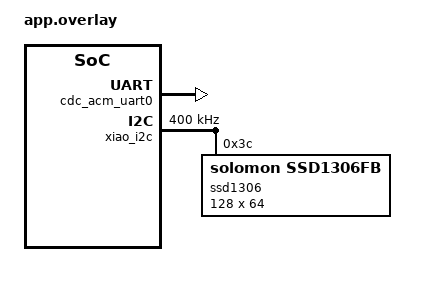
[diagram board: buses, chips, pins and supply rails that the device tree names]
&zephyr_udc0 {
	cdc_acm_uart0: cdc_acm_uart0 {
		compatible = "zephyr,cdc-acm-uart";
	};
};

&xiao_i2c {
	status="okay";
	clock-frequency=<I2C_BITRATE_FAST>;

	ssd1306: ssd1306@3c {
		compatible = "solomon,ssd1306fb";
		status = "okay";
		reg = <0x3c>;
		width = <128>;
		height = <64>;
		segment-offset  = <0>;
		page-offset     = <0>;
		display-offset  = <0>;
		multiplex-ratio = <31>;
		prechargep      = <0xD1>;
		segment-remap;
		com-invdir;
		com-sequential;
	};
	
}; 

/ { 
	chosen {
		zephyr,console = &cdc_acm_uart0;
		zephyr,display = &ssd1306;
	};
};


